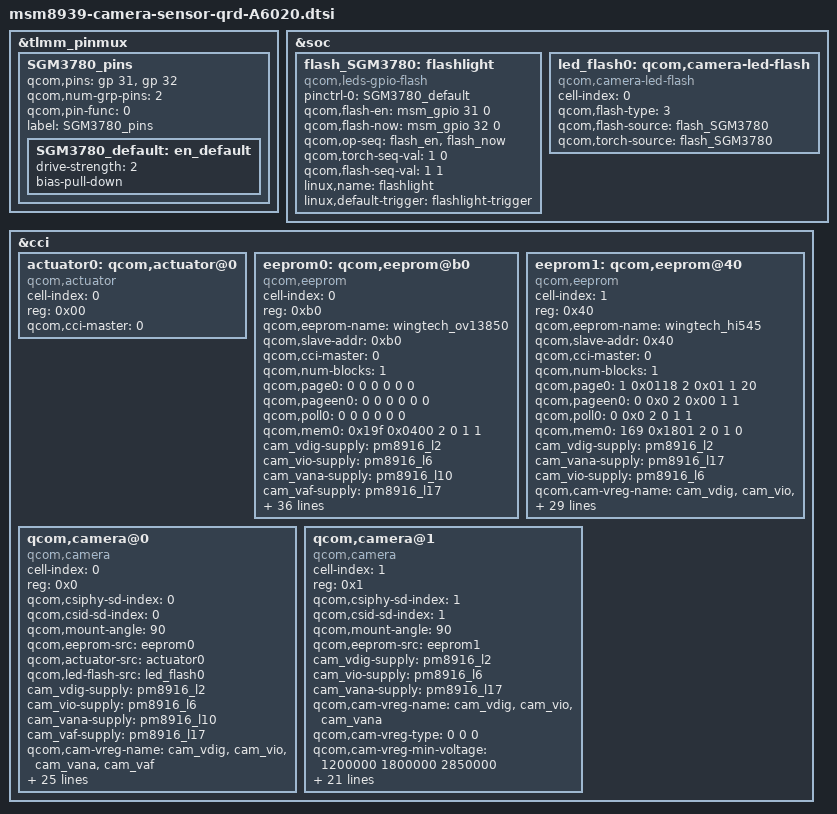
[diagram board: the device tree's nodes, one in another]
/*
 * Copyright (c) 2014, The Linux Foundation. All rights reserved.
 *
 * This program is free software; you can redistribute it and/or modify
 * it under the terms of the GNU General Public License version 2 and
 * only version 2 as published by the Free Software Foundation.
 *
 * This program is distributed in the hope that it will be useful,
 * but WITHOUT ANY WARRANTY; without even the implied warranty of
 * MERCHANTABILITY or FITNESS FOR A PARTICULAR PURPOSE.  See the
 * GNU General Public License for more details.
 */


&tlmm_pinmux {
	SGM3780_pins {
		qcom,pins = <&gp 31>, <&gp 32>;
		qcom,num-grp-pins = <2>;
		qcom,pin-func = <0>;
		label = "SGM3780_pins";
		SGM3780_default: en_default {
			  drive-strength = <2>;
			  bias-pull-down;
		};
	};
};

&soc {
	flash_SGM3780:flashlight {
		compatible = "qcom,leds-gpio-flash";
		status = "okay";
		pinctrl-names = "flash_default";
		pinctrl-0 = <&SGM3780_default>;
		qcom,flash-en = <&msm_gpio 31 0>;
		qcom,flash-now = <&msm_gpio 32 0>;
		qcom,op-seq = "flash_en", "flash_now";
		qcom,torch-seq-val = <1 0>;
		qcom,flash-seq-val = <1 1>;
		linux,name = "flashlight";
		linux,default-trigger = "flashlight-trigger";
	};

	led_flash0: qcom,camera-led-flash {
		cell-index = <0>;
		compatible = "qcom,camera-led-flash";
		qcom,flash-type = <3>;
		qcom,flash-source = <&flash_SGM3780>;
		qcom,torch-source = <&flash_SGM3780>;
	};
};

&cci {
	actuator0: qcom,actuator@0 {
		cell-index = <0>;
		reg = <0x00>;
		compatible = "qcom,actuator";
		qcom,cci-master = <0>;
	};

	eeprom0: qcom,eeprom@b0 {
		cell-index = <0>;
		reg = <0xb0>;
		qcom,eeprom-name = "wingtech_ov13850";
		compatible = "qcom,eeprom";
		qcom,slave-addr = <0xb0>;
		qcom,cci-master = <0>;
		qcom,num-blocks = <1>;
		qcom,page0 = <0 0 0 0 0 0>;
		qcom,pageen0 = <0 0 0 0 0 0>;
		qcom,poll0 = <0 0 0 0 0 0>;
		qcom,mem0 = <0x19f 0x0400 2 0 1 1>;
		cam_vdig-supply = <&pm8916_l2>;
		cam_vio-supply = <&pm8916_l6>;
		cam_vana-supply = <&pm8916_l10>;
		cam_vaf-supply = <&pm8916_l17>;
		qcom,cam-vreg-name = "cam_vdig", "cam_vio", "cam_vana",
							"cam_vaf";
		qcom,cam-vreg-type = <0 0 0 0>;
		qcom,cam-vreg-min-voltage = <1200000 1800000 2800000 2850000>;
		qcom,cam-vreg-max-voltage = <1200000 1800000 2800000 2850000>;
		qcom,cam-vreg-op-mode = <200000 200000 80000 100000>;

		pinctrl-names = "cam_default", "cam_suspend";
		pinctrl-0 = <&cam_sensor_mclk0_default &cam_sensor_rear_default>;
		pinctrl-1 = <&cam_sensor_mclk0_sleep &cam_sensor_rear_sleep>;
		gpios = <&msm_gpio 26 0>,
			<&msm_gpio 35 0>,
			<&msm_gpio 34 0>,
			<&msm_gpio 21 0>;
		qcom,gpio-reset = <1>;
		qcom,gpio-standby = <2>;
		qcom,gpio-vdig = <3>;
		qcom,gpio-req-tbl-num = <0 1 2 3>;
		qcom,gpio-req-tbl-flags = <1 0 0 0>;
		qcom,gpio-req-tbl-label = "CAMIF_MCLK",
			"CAM_RESET1",
			"CAM_STANDBY",
			"CAM_VDIG";
		qcom,cam-power-seq-type = "sensor_vreg",
			"sensor_vreg",
			"sensor_vreg",
			"sensor_vreg",
			"sensor_gpio", 
			"sensor_gpio",
			"sensor_gpio",
			"sensor_gpio", 
			"sensor_clk";
		qcom,cam-power-seq-val = "cam_vio",
			"cam_vana",
			"cam_vdig",
			"cam_vaf",
			"sensor_gpio_standby",
			"sensor_gpio_reset",
			"sensor_gpio_standby",
			"sensor_gpio_reset",
			"sensor_cam_mclk" ;
		qcom,cam-power-seq-cfg-val = <1 1 1 1 0 0 1 1 23880000>;
		qcom,cam-power-seq-delay = <1 10 10 5 10 10 10 10 10>;
		clocks = <&clock_gcc clk_mclk0_clk_src>,
			<&clock_gcc clk_gcc_camss_mclk0_clk>;
		clock-names = "cam_src_clk", "cam_clk";
	};
	eeprom1: qcom,eeprom@40 {	
			cell-index = <1>;
			reg = <0x40>;
			qcom,eeprom-name = "wingtech_hi545";
			compatible = "qcom,eeprom";
			qcom,slave-addr = <0x40>;
			qcom,cci-master = <0>;	
		   qcom,num-blocks = <1>;
		   
		   qcom,page0 = <1 0x0118 2 0x01 1 20>;
		   qcom,pageen0 = <0 0x0 2 0x00 1 1>;
		   qcom,poll0 = <0 0x0 2 0 1 1>;
		   qcom,mem0 = <169 0x1801 2 0 1 0>;

			cam_vdig-supply = <&pm8916_l2>;
			cam_vana-supply = <&pm8916_l17>;
			cam_vio-supply = <&pm8916_l6>;
			qcom,cam-vreg-name = "cam_vdig", "cam_vio", "cam_vana";
			qcom,cam-vreg-min-voltage = <1200000 0 2850000>;
			qcom,cam-vreg-max-voltage = <1200000 0 2850000>;
			qcom,cam-vreg-op-mode = <200000 0 80000>;
			pinctrl-names = "cam_default", "cam_suspend";
			pinctrl-0 = <&cam_sensor_mclk1_default &cam_sensor_front_default>;
			pinctrl-1 = <&cam_sensor_mclk1_sleep &cam_sensor_front_sleep>;
			gpios = <&msm_gpio 27 0>,
				<&msm_gpio 17 0>,
				<&msm_gpio 28 0>,
				<&msm_gpio 33 0>;
			qcom,gpio-vdig = <1>;
			qcom,gpio-reset = <2>;
			qcom,gpio-standby = <3>;
			qcom,gpio-req-tbl-num = <0 1 2 3>;
			qcom,gpio-req-tbl-flags = <1 0 0 0>;
			qcom,gpio-req-tbl-label = "CAMIF_MCLK",
				"CAM_VDIG",
				"SCAM_RESET",
				"SCAM_STANDBY";
			qcom,cam-power-seq-type = "sensor_vreg",
				"sensor_vreg", "sensor_vreg",
				"sensor_gpio", "sensor_gpio","sensor_gpio",
				"sensor_clk";
			qcom,cam-power-seq-val = "cam_vio",
				"cam_vana", "cam_vdig",
				"sensor_gpio_vdig",
				"sensor_gpio_reset",
				"sensor_gpio_standby",
				"sensor_cam_mclk" ;
			qcom,cam-power-seq-cfg-val = <1 1 1 1 1 1 23880000>;
			qcom,cam-power-seq-delay = <5 5 5 5 10 10 5>;

			clocks = <&clock_gcc clk_mclk1_clk_src>,
				<&clock_gcc clk_gcc_camss_mclk1_clk>;
			clock-names = "cam_src_clk", "cam_clk";
		};

	qcom,camera@0 {
		cell-index = <0>;
		compatible = "qcom,camera";
		reg = <0x0>;
		qcom,csiphy-sd-index = <0>;
		qcom,csid-sd-index = <0>;
		qcom,mount-angle = <90>;
		qcom,eeprom-src = <&eeprom0>;
		qcom,actuator-src = <&actuator0>;
		qcom,led-flash-src = <&led_flash0>;
		cam_vdig-supply = <&pm8916_l2>;
		cam_vio-supply = <&pm8916_l6>;
		cam_vana-supply = <&pm8916_l10>;
		cam_vaf-supply = <&pm8916_l17>;
		qcom,cam-vreg-name = "cam_vdig", "cam_vio", "cam_vana","cam_vaf";
		qcom,cam-vreg-type = <0 0 0 0>;
		qcom,cam-vreg-min-voltage = <1200000 1800000 2800000 2850000>;
		qcom,cam-vreg-max-voltage = <1200000 1800000 2800000 2850000>;
		qcom,cam-vreg-op-mode = <200000 200000 80000 100000>;
		pinctrl-names = "cam_default", "cam_suspend";
		pinctrl-0 = <&cam_sensor_mclk0_default &cam_sensor_rear_default>;
		pinctrl-1 = <&cam_sensor_mclk0_sleep &cam_sensor_rear_sleep>;
		gpios = <&msm_gpio 26 0>,
			<&msm_gpio 35 0>,
			<&msm_gpio 34 0>,
			<&msm_gpio 17 0>;
		qcom,gpio-reset = <1>;
		qcom,gpio-standby = <2>;
		qcom,gpio-vdig = <3>;
		qcom,gpio-req-tbl-num = <0 1 2 3>;
		qcom,gpio-req-tbl-flags = <1 0 0 0>;
		qcom,gpio-req-tbl-label = "CAMIF_MCLK",
			"CAM_RESET1",
			"CAM_STANDBY",
			"CAM_VDIG";
		qcom,sensor-position = <0>;
		qcom,sensor-mode = <0>;
		qcom,cci-master = <0>;
		status = "ok";
		clocks = <&clock_gcc clk_mclk0_clk_src>,
				<&clock_gcc clk_gcc_camss_mclk0_clk>;
		clock-names = "cam_src_clk", "cam_clk";
	};

	qcom,camera@1 {
		cell-index = <1>;
		compatible = "qcom,camera";
		reg = <0x1>;
		qcom,csiphy-sd-index = <1>;
		qcom,csid-sd-index = <1>;
		qcom,mount-angle = <90>;
		qcom,eeprom-src = <&eeprom1>;
		cam_vdig-supply = <&pm8916_l2>;
		cam_vio-supply = <&pm8916_l6>;
		cam_vana-supply = <&pm8916_l17>;

		qcom,cam-vreg-name = "cam_vdig", "cam_vio", "cam_vana";
		qcom,cam-vreg-type = <0 0 0>;
		qcom,cam-vreg-min-voltage = <1200000 1800000 2850000>;
		qcom,cam-vreg-max-voltage = <1200000 1800000 2850000>;
		qcom,cam-vreg-op-mode = <200000 80000 100000>;
		pinctrl-names = "cam_default", "cam_suspend";
		pinctrl-0 = <&cam_sensor_mclk1_default &cam_sensor_front_default>;
		pinctrl-1 = <&cam_sensor_mclk1_sleep &cam_sensor_front_sleep>;
		gpios = <&msm_gpio 27 0>,
			<&msm_gpio 17 0>,
			<&msm_gpio 28 0>,
			<&msm_gpio 33 0>;
		qcom,gpio-vdig = <1>;
		qcom,gpio-reset = <2>;
		qcom,gpio-standby = <3>;
		qcom,gpio-req-tbl-num = <0 1 2 3>;
		qcom,gpio-req-tbl-flags = <1 0 0 0>;
		qcom,gpio-req-tbl-label = "CAMIF_MCLK",
			"CAM_VDIG",
			"CAM_RESET",
			"CAM_STANDBY";
		qcom,sensor-position = <1>;
		qcom,sensor-mode = <0>;
		qcom,cci-master = <0>;
		status = "ok";
		clocks = <&clock_gcc clk_mclk1_clk_src>,
				<&clock_gcc clk_gcc_camss_mclk1_clk>;
		clock-names = "cam_src_clk", "cam_clk";
	};
};
